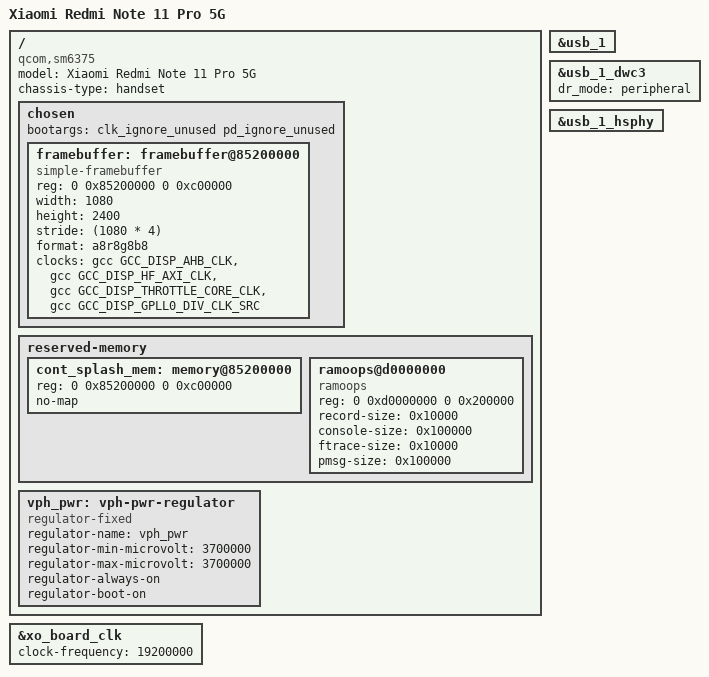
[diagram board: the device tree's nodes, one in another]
/dts-v1/;

#include "sm6375.dtsi"
#include "pmr735a.dtsi"
#include "pmk8350.dtsi"
#include "pm6125.dtsi"

/* PM6125 PON is used and we can't have duplicate labels */
/delete-node/ &pmk8350_pon;

/ {
	model = "Xiaomi Redmi Note 11 Pro 5G";
	compatible = "qcom,sm6375";
	chassis-type = "handset";

	chosen {
		#address-cells = <2>;
		#size-cells = <2>;
		ranges;

		bootargs = "clk_ignore_unused pd_ignore_unused";

		framebuffer: framebuffer@85200000 {
			compatible = "simple-framebuffer";
			reg = <0 0x85200000 0 0xc00000>;

			width = <1080>;
			height = <2400>;
			stride = <(1080 * 4)>;
			format = "a8r8g8b8";
			/*
			 * That's (going to be) a lot of clocks, but it's necessary due
			 * to unused clk cleanup & no panel driver yet
			 */
			clocks = <&gcc GCC_DISP_AHB_CLK>,
				 <&gcc GCC_DISP_HF_AXI_CLK>,
				 <&gcc GCC_DISP_THROTTLE_CORE_CLK>,
				 <&gcc GCC_DISP_GPLL0_DIV_CLK_SRC>;   			    
		};
	};

	reserved-memory {
		cont_splash_mem: memory@85200000 {
			reg = <0 0x85200000 0 0xc00000>;
			no-map;
		};
		
        ramoops@d0000000 {
			compatible = "ramoops";
			reg = <0 0xd0000000 0 0x200000>;
			record-size = <0x10000>;
			console-size = <0x100000>;
			ftrace-size = <0x10000>;
			pmsg-size = <0x100000>;
		};
	};

	vph_pwr: vph-pwr-regulator {
		compatible = "regulator-fixed";
		regulator-name = "vph_pwr";
		regulator-min-microvolt = <3700000>;
		regulator-max-microvolt = <3700000>;
		regulator-always-on;
		regulator-boot-on;
	};
};

&usb_1 {
	status = "okay";
};

&usb_1_dwc3 {
	dr_mode = "peripheral";
};

&usb_1_hsphy {
	status = "okay";
};

&xo_board_clk {
	clock-frequency = <19200000>;
};
